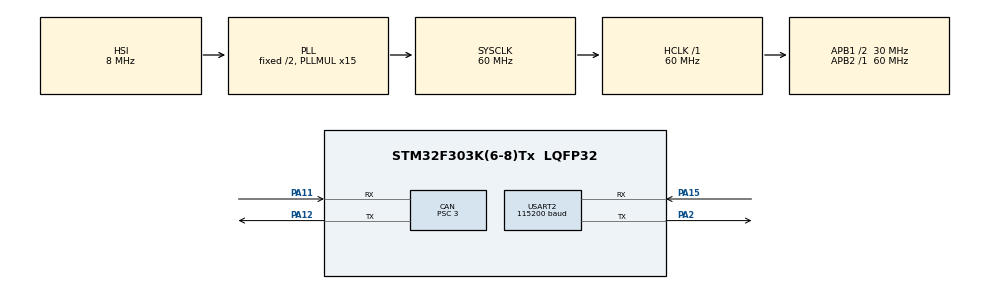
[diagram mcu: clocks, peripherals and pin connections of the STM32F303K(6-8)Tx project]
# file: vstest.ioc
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CAN.BS1=CAN_BS1_15TQ
CAN.BS2=CAN_BS2_4TQ
CAN.CalculateBaudRate=500000
CAN.CalculateTimeBit=2000
CAN.CalculateTimeQuantum=100.0
CAN.Prescaler=3
Mcu.Family=STM32F3
Mcu.Name=STM32F303K(6-8)Tx
Mcu.Package=LQFP32
NVIC.PriorityGroup=NVIC_PRIORITYGROUP_4
PA11.Mode=CAN_Activate
PA11.Signal=CAN_RX
PA12.Mode=CAN_Activate
PA12.Signal=CAN_TX
PA13.GPIO_Label=SWDIO
PA13.Signal=SYS_JTMS-SWDIO
PA14.GPIO_Label=SWCLK
PA14.Signal=SYS_JTCK-SWCLK
PA15.GPIO_ModeDefaultPP=GPIO_MODE_AF_PP
PA15.GPIO_PuPd=GPIO_NOPULL
PA15.GPIO_Speed=GPIO_SPEED_FREQ_HIGH
PA15.Mode=Asynchronous
PA15.Signal=USART2_RX
PA2.GPIO_ModeDefaultPP=GPIO_MODE_AF_PP
PA2.GPIO_PuPd=GPIO_NOPULL
PA2.GPIO_Speed=GPIO_SPEED_FREQ_HIGH
PA2.Mode=Asynchronous
PA2.Signal=USART2_TX
PF0\ /\ OSC_IN.GPIO_Label=MCO
PF0\ /\ OSC_IN.Signal=RCC_OSC_IN
ProjectManager.HeapSize=0x200
ProjectManager.StackSize=0x400
ProjectManager.TargetToolchain=STM32CubeIDE
RCC.AHBFreq_Value=60000000
RCC.APB1CLKDivider=RCC_HCLK_DIV2
RCC.APB1Freq_Value=30000000
RCC.APB1TimFreq_Value=60000000
RCC.APB2Freq_Value=60000000
RCC.APB2TimFreq_Value=60000000
RCC.CortexFreq_Value=60000000
RCC.HCLKFreq_Value=60000000
RCC.HSE_VALUE=8000000
RCC.HSI_VALUE=8000000
RCC.PLLMUL=RCC_PLL_MUL15
RCC.SYSCLKFreq_VALUE=60000000
RCC.SYSCLKSourceVirtual=RCC_SYSCLKSOURCE_PLLCLK
USART2.BaudRate=115200
USART2.VirtualMode-Asynchronous=VM_ASYNC
board=NUCLEO-F303K8

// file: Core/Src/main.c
/* USER CODE BEGIN Header */
/**
  ******************************************************************************
  * @file           : main.c
  * @brief          : Main program body
  ******************************************************************************
  * @attention
  *
  * Copyright (c) 2023 STMicroelectronics.
  * All rights reserved.
  *
  * This software is licensed under terms that can be found in the LICENSE file
  * in the root directory of this software component.
  * If no LICENSE file comes with this software, it is provided AS-IS.
  *
  ******************************************************************************
  */
/* USER CODE END Header */
#include "main.h"
#include "can.h"
#include "usart.h"
#include "gpio.h"

/* USER CODE BEGIN Includes */
#include <string.h>
/* USER CODE END Includes */

void SystemClock_Config(void);

/* USER CODE BEGIN 0 */
void prints(const char* inputString) {
    // 文字列の長さを計算
    size_t length = strlen(inputString);
    HAL_UART_Transmit(&huart2, inputString, length, 100);
}
/* USER CODE END 0 */

int main(void)
{

  /* MCU Configuration--------------------------------------------------------*/

  /* Reset of all peripherals, Initializes the Flash interface and the Systick. */
  HAL_Init();

  /* Configure the system clock */
  SystemClock_Config();

  /* Initialize all configured peripherals */
  MX_GPIO_Init();
  MX_USART2_UART_Init();
  MX_CAN_Init();
  /* USER CODE BEGIN 2 */
  static CAN_TxHeaderTypeDef TxHeader;
 //static CAN_RxHeaderTypeDef RxHeader;
  /* USER CODE END 2 */

  /* Infinite loop */
  while (1)
  {

	 HAL_CAN_Start(&hcan);
	 	 int CANID = 0x555;
	 	 uint32_t TxMailbox;
	 	 uint8_t TxData[8];

	 	 if(HAL_CAN_GetTxMailboxesFreeLevel(&hcan) != 0)
	 	 {
	 		 TxHeader.StdId = CANID;
	 		 TxHeader.RTR = CAN_RTR_DATA;
	 		 TxHeader.IDE = CAN_ID_STD;
	 		 TxHeader.DLC = 8;
	 		 TxHeader.TransmitGlobalTime = DISABLE;

       TxData[0]='h';
       TxData[1]='e';
       TxData[2]='l';
       TxData[3]='l';
       TxData[4]='o';
       TxData[5]='s';
       TxData[6]='t';
       TxData[0]='m';

       if(HAL_CAN_AddTxMessage(&hcan,&TxHeader,TxData,&TxMailbox) != HAL_OK )
       {
        Error_Handler();
       }

       prints("CAN Ok!");

	 	 }
     HAL_Delay(1000);
  }
}

void SystemClock_Config(void)
{
  RCC_OscInitTypeDef RCC_OscInitStruct = {0};
  RCC_ClkInitTypeDef RCC_ClkInitStruct = {0};

  /** Initializes the RCC Oscillators according to the specified parameters
  * in the RCC_OscInitTypeDef structure.
  */
  RCC_OscInitStruct.OscillatorType = RCC_OSCILLATORTYPE_HSI;
  RCC_OscInitStruct.HSIState = RCC_HSI_ON;
  RCC_OscInitStruct.HSICalibrationValue = RCC_HSICALIBRATION_DEFAULT;
  RCC_OscInitStruct.PLL.PLLState = RCC_PLL_ON;
  RCC_OscInitStruct.PLL.PLLSource = RCC_PLLSOURCE_HSI;
  RCC_OscInitStruct.PLL.PLLMUL = RCC_PLL_MUL15;
  if (HAL_RCC_OscConfig(&RCC_OscInitStruct) != HAL_OK)
  {
    Error_Handler();
  }

  /** Initializes the CPU, AHB and APB buses clocks
  */
  RCC_ClkInitStruct.ClockType = RCC_CLOCKTYPE_HCLK|RCC_CLOCKTYPE_SYSCLK
                              |RCC_CLOCKTYPE_PCLK1|RCC_CLOCKTYPE_PCLK2;
  RCC_ClkInitStruct.SYSCLKSource = RCC_SYSCLKSOURCE_PLLCLK;
  RCC_ClkInitStruct.AHBCLKDivider = RCC_SYSCLK_DIV1;
  RCC_ClkInitStruct.APB1CLKDivider = RCC_HCLK_DIV2;
  RCC_ClkInitStruct.APB2CLKDivider = RCC_HCLK_DIV1;

  if (HAL_RCC_ClockConfig(&RCC_ClkInitStruct, FLASH_LATENCY_2) != HAL_OK)
  {
    Error_Handler();
  }
}

void Error_Handler(void)
{
  __disable_irq();
  while (1)
  {
  }
}
